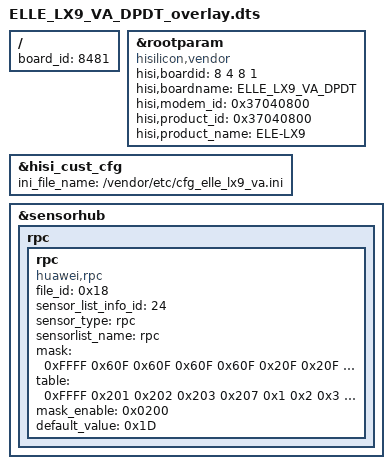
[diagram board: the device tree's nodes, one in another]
/**
 * Copyright (C) 2014 Hisilicon Ltd.
 *
 *  This program is free software; you can redistribute it and/or modify
 *  it under the terms of the GNU General Public License version 2 as
 *  publishhed by the Free Software Foundation.
 */

/dts-v1/;
/plugin/;
/include/ "ELLE_LX9_VA_overlay.dtsi"
/include/ "ELLE_LX9_VA_DPDT_pin.dtsi"
/include/ "ELLE_LX9_VA_DPDT_modem_pin.dtsi"

/ {
    board_id = <8481>;
};
    &rootparam{
		compatible = "hisilicon,vendor";
		hisi,boardid = <8 4 8 1>;
		hisi,boardname = "ELLE_LX9_VA_DPDT";
		hisi,modem_id = <0x37040800>;
		hisi,product_id = <0x37040800>;
		hisi,product_name = "ELE-LX9";
	};

    /*hisi customize*/
    &hisi_cust_cfg {
        ini_file_name = "/vendor/etc/cfg_elle_lx9_va.ini";
    };
	&sensorhub{
              	rpc{
                       rpc{
                             compatible = "huawei,rpc";
                             file_id = <0x18>;
                             sensor_list_info_id = <24>;
                             sensor_type = "rpc";
                             sensorlist_name = "rpc";
                             mask = <0xFFFF 0x60F 0x60F 0x60F 0x60F 0x20F 0x20F 0x20F
                                     0x20F 0xFFFF 0xFFFF 0xFFFF 0xFFFF 0xFFFF 0xFFFF 0xFFFF
                                     0xFFFF 0xFFFF 0xFFFF 0xFFFF 0xFFFF 0xFFFF 0xFFFF 0xFFFF
                                     0xFFFF 0xFFFF 0xFFFF 0xFFFF 0xFFFF 0xF 0xFFFF 0xFFFF>;
                            table = <0xFFFF 0x201 0x202 0x203 0x207 0x1 0x2 0x3
                                     0x7 0xFFFF 0xFFFF 0xFFFF 0xFFFF 0xFFFF 0xFFFF 0xFFFF
                                     0xFFFF 0xFFFF 0xFFFF 0xFFFF 0xFFFF 0xFFFF 0xFFFF 0xFFFF
                                     0xFFFF 0xFFFF 0xFFFF 0xFFFF 0xFFFF 0x0 0xFFFF 0xFFFF>;
							mask_enable = <0x0200>;
                            default_value = <0x1D>;
                            status = "ok";
                         };
                 };
	};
